# STM32H7x7_CM7 register map
File version: 1.0
CPU: CM7 r0p1, little endian, MPU, FPU, 4 interrupt priority bits
Registers are 32-bit, read-write, reset 0x0 unless marked. A register's access mark holds for its fields unless they carry their own. Offsets are from the block's base; [hi:lo] are bit positions.

## RNG
Base 0x48021800
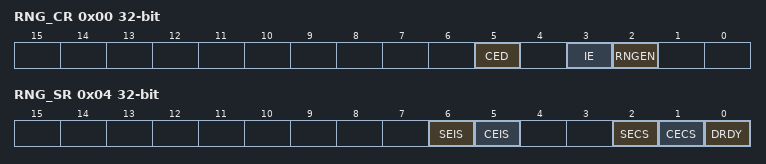
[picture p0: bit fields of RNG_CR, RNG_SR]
0x00 RNG_CR — RNG control register
  [5] CED — Clock error detection Note: The clock error detection can be used only when ck_rc48 or ck_pll1_q (ck_pll1_q = 48MHz) source is selected otherwise, CED bit must be equal to 1. The clock error detection cannot be enabled nor disabled on the fly when RNG peripheral is enabled, to enable or disable CED the RNG must be disabled.
  [3] IE — Interrupt enable
  [2] RNGEN — Random number generator enable
0x04 RNG_SR access per field — RNG status register
  [6] SEIS rw — Seed error interrupt status This bit is set at the same time as SECS. It is cleared by writing it to 0. ** More than 64 consecutive bits at the same value (0 or 1) ** More than 32 consecutive alternances of 0 and 1 (0101010101...01) An interrupt is pending if IE = 1 in the RNG_CR register.
  [5] CEIS rw — Clock error interrupt status This bit is set at the same time as CECS. It is cleared by writing it to 0. An interrupt is pending if IE = 1 in the RNG_CR register. Note: This bit is meaningless if CED (Clock error detection) bit in RNG_CR is equal to 1.
  [2] SECS ro — Seed error current status ** More than 64 consecutive bits at the same value (0 or 1) ** More than 32 consecutive alternances of 0 and 1 (0101010101...01)
  [1] CECS ro — Clock error current status Note: This bit is meaningless if CED (Clock error detection) bit in RNG_CR is equal to 1.
  [0] DRDY ro — Data ready Note: If IE=1 in RNG_CR, an interrupt is generated when DRDY=1. It can rise when the peripheral is disabled. When the output buffer becomes empty (after reading RNG_DR), this bit returns to 0 until a new random value is generated.
0x08 RNG_DR ro — The RNG_DR register is a read-only register that delivers a 32-bit random value when read. The content of this register is valid when DRDY= 1, even if RNGEN=0.
  [31:0] RNDATA — Random data 32-bit random data which are valid when DRDY=1.

## VREFBUF
Base 0x58003C00
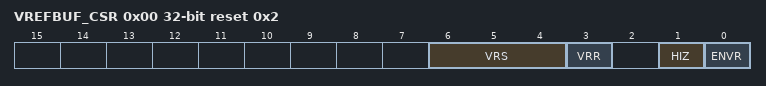
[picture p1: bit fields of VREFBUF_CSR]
0x00 VREFBUF_CSR access per field reset 0x2 — VREFBUF control and status register
  [6:4] VRS rw — Voltage reference scale These bits select the value generated by the voltage reference buffer. Other: Reserved
  [3] VRR ro — Voltage reference buffer ready
  [1] HIZ rw — High impedance mode This bit controls the analog switch to connect or not the VREF+ pin. Refer to Table196: VREF buffer modes for the mode descriptions depending on ENVR bit configuration.
  [0] ENVR rw — Voltage reference buffer mode enable This bit is used to enable the voltage reference buffer mode.
0x04 VREFBUF_CCR — VREFBUF calibration control register
  [5:0] TRIM — Trimming code These bits are automatically initialized after reset with the trimming value stored in the Flash memory during the production test. Writing into these bits allows to tune the internal reference buffer voltage.

## WWDG1 — WWDG
Base 0x40002C00
Same registers: WWDG2 0x50003000
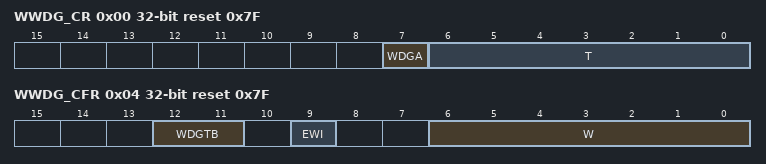
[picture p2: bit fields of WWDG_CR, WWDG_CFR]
0x00 WWDG_CR reset 0x7F — Control register
  [7] WDGA — Activation bit This bit is set by software and only cleared by hardware after a reset. When WDGA=1, the watchdog can generate a reset.
  [6:0] T — 7-bit counter (MSB to LSB) These bits contain the value of the watchdog counter. It is decremented every (4096 x 2WDGTB[1:0]) PCLK cycles. A reset is produced when it is decremented from 0x40 to 0x3F (T6 becomes cleared).
0x04 WWDG_CFR reset 0x7F — Configuration register
  [12:11] WDGTB — Timer base The time base of the prescaler can be modified as follows:
  [9] EWI — Early wakeup interrupt When set, an interrupt occurs whenever the counter reaches the value 0x40. This interrupt is only cleared by hardware after a reset.
  [6:0] W — 7-bit window value These bits contain the window value to be compared to the downcounter.
0x08 WWDG_SR — Status register
  [0] EWIF — Early wakeup interrupt flag This bit is set by hardware when the counter has reached the value 0x40. It must be cleared by software by writing 0. A write of 1 has no effect. This bit is also set if the interrupt is not enabled.
